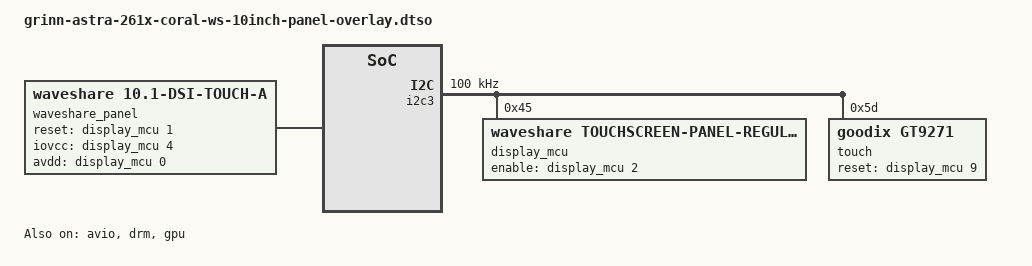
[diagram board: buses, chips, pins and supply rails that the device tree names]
/*
 * Device-tree overlay for the Waveshare 10.1" DSI Touch (A) panel
 * (SKU 30052) on the Grinn Astra 2619 Coral board.
 *
 *   Display IC : Jadard JD9365 (1280x800 native portrait, MIPI-DSI 2-lane)
 *   Touch IC   : Goodix GT9271
 *   Panel MCU  : Waveshare touchscreen panel regulator (I2C @ 0x45)
 *
 * The DSI host (syna_drm) is configured with the panel's native portrait
 * timings (800x1280) and sends the JD9365 init DCS sequence itself. The
 * panel-waveshare-touch kernel driver registers the drm_panel that the
 * DSI host attaches to via of_drm_find_panel(); it sequences the iovcc /
 * avdd / reset GPIOs that the Waveshare panel MCU exposes through the
 * waveshare-panel-regulator gpio_chip.
 */

/dts-v1/;
/plugin/;

#include <dt-bindings/gpio/gpio.h>

/ {
	compatible = "grinn,grinn-astra-2619-coral";
};

/*
 * Add the panel adapter node at the device-tree root via path-based
 * fragment syntax. The simpler `/ { ... };` form above is treated by
 * /plugin/ overlays as a root-match assertion only — subnodes inside
 * it are NOT emitted as fragments and never reach the live DT.
 *
 * &{/} forces a proper fragment with target = <&{/}>, which makes the
 * applicator add the child node at root. The kernel's of_platform
 * populate then creates a platform_device that panel-waveshare-dsi-v2
 * can bind to.
 */
&{/} {
	waveshare_panel: waveshare-panel {
		compatible = "waveshare,10.1-dsi-touch-a";
		status = "okay";
		reset-gpios = <&display_mcu 1 GPIO_ACTIVE_HIGH>;
		iovcc-gpios = <&display_mcu 4 GPIO_ACTIVE_HIGH>;
		avdd-gpios = <&display_mcu 0 GPIO_ACTIVE_HIGH>;
	};
};

&avio {
	status = "okay";
};

&drm {
	status = "okay";

	dsi_panel {
		status = "okay";

		backlight = <&display_mcu>;
		compatible_panel = "waveshare,10.1-dsi-touch-a";

		ACTIVE_WIDTH = <800>;
		HFP = <40>;
		HSYNCWIDTH = <20>;
		HBP = <20>;
		ACTIVE_HEIGHT = <1280>;
		VFP = <20>;
		VSYNCWIDTH = <20>;
		VBP = <4>;
		FREQ = <70000>;
		bits_per_pixel = <24>;
		busformat = <0>;

		HTOTAL = <880>;
		Lanes = /bits/ 8 <2>;
		Vid_mode = /bits/ 8 <1>;
		virtual_chan = /bits/ 8 <0>;
		Clk_Lane_Polarity = /bits/ 8 <0>;
		Data_Lane_Polarity = /bits/ 8 <0>;
		Recv_ack = /bits/ 8 <0>;
		Loosely_18 = /bits/ 8 <0>;
		H_polarity = /bits/ 8 <1>;
		V_Polarity = /bits/ 8 <1>;
		Data_Polarity = /bits/ 8 <1>;
		Eotp_tx = /bits/ 8 <0>;
		Eotp_rx = /bits/ 8 <0>;
		non-Continuous_clk = /bits/ 8 <1>;
		dpi_lp_cmd = /bits/ 8 <1>;
		Color_coding = /bits/ 8 <5>;
		Chunks = <0>;
		Null_Pkt = <0>;
		Byte_clk = <105000>;

		/*
		 * JD9365 init sequence transcribed from
		 * raspberrypi/linux rpi-6.12.y
		 *   drivers/gpu/drm/panel/panel-waveshare-dsi-v2.c
		 *   ws_panel_10_1_a_init[]
		 *
		 * Encoding (drivers/synaptics/.../drm/asxxx/dsi/includes.h):
		 *   0x05 LEN <reg>           DCS short write, 0 param
		 *   0x15 LEN <reg> <val>     DCS short write, 1 param
		 *   0xFF <us LE u32>         delay in microseconds
		 *
		 * 201 DCS commands + 2 delays = 812 bytes.
		 */
		command = /bits/ 8 <
				0x15 0x02 0xE0 0x00 0x15 0x02 0xE1 0x93
				0x15 0x02 0xE2 0x65 0x15 0x02 0xE3 0xF8
				0x15 0x02 0x80 0x01 0x15 0x02 0xE0 0x01
				0x15 0x02 0x00 0x00 0x15 0x02 0x01 0x38
				0x15 0x02 0x03 0x10 0x15 0x02 0x04 0x38
				0x15 0x02 0x0C 0x74 0x15 0x02 0x17 0x00
				0x15 0x02 0x18 0xAF 0x15 0x02 0x19 0x00
				0x15 0x02 0x1A 0x00 0x15 0x02 0x1B 0xAF
				0x15 0x02 0x1C 0x00 0x15 0x02 0x35 0x26
				0x15 0x02 0x37 0x09 0x15 0x02 0x38 0x04
				0x15 0x02 0x39 0x00 0x15 0x02 0x3A 0x01
				0x15 0x02 0x3C 0x78 0x15 0x02 0x3D 0xFF
				0x15 0x02 0x3E 0xFF 0x15 0x02 0x3F 0x7F
				0x15 0x02 0x40 0x06 0x15 0x02 0x41 0xA0
				0x15 0x02 0x42 0x81 0x15 0x02 0x43 0x1E
				0x15 0x02 0x44 0x0D 0x15 0x02 0x45 0x28
				/* 0x15 0x02 0x4A 0x35 */ /* Built-in self-test (BIST) command */
				0x15 0x02 0x55 0x02 0x15 0x02 0x57 0x69
				0x15 0x02 0x59 0x0A 0x15 0x02 0x5A 0x2A
				0x15 0x02 0x5B 0x17 0x15 0x02 0x5D 0x7F
				0x15 0x02 0x5E 0x6A 0x15 0x02 0x5F 0x5B
				0x15 0x02 0x60 0x4F 0x15 0x02 0x61 0x4A
				0x15 0x02 0x62 0x3D 0x15 0x02 0x63 0x41
				0x15 0x02 0x64 0x2A 0x15 0x02 0x65 0x44
				0x15 0x02 0x66 0x43 0x15 0x02 0x67 0x44
				0x15 0x02 0x68 0x62 0x15 0x02 0x69 0x52
				0x15 0x02 0x6A 0x59 0x15 0x02 0x6B 0x4C
				0x15 0x02 0x6C 0x48 0x15 0x02 0x6D 0x3A
				0x15 0x02 0x6E 0x26 0x15 0x02 0x6F 0x00
				0x15 0x02 0x70 0x7F 0x15 0x02 0x71 0x6A
				0x15 0x02 0x72 0x5B 0x15 0x02 0x73 0x4F
				0x15 0x02 0x74 0x4A 0x15 0x02 0x75 0x3D
				0x15 0x02 0x76 0x41 0x15 0x02 0x77 0x2A
				0x15 0x02 0x78 0x44 0x15 0x02 0x79 0x43
				0x15 0x02 0x7A 0x44 0x15 0x02 0x7B 0x62
				0x15 0x02 0x7C 0x52 0x15 0x02 0x7D 0x59
				0x15 0x02 0x7E 0x4C 0x15 0x02 0x7F 0x48
				0x15 0x02 0x80 0x3A 0x15 0x02 0x81 0x26
				0x15 0x02 0x82 0x00 0x15 0x02 0xE0 0x02
				0x15 0x02 0x00 0x42 0x15 0x02 0x01 0x42
				0x15 0x02 0x02 0x40 0x15 0x02 0x03 0x40
				0x15 0x02 0x04 0x5E 0x15 0x02 0x05 0x5E
				0x15 0x02 0x06 0x5F 0x15 0x02 0x07 0x5F
				0x15 0x02 0x08 0x5F 0x15 0x02 0x09 0x57
				0x15 0x02 0x0A 0x57 0x15 0x02 0x0B 0x77
				0x15 0x02 0x0C 0x77 0x15 0x02 0x0D 0x47
				0x15 0x02 0x0E 0x47 0x15 0x02 0x0F 0x45
				0x15 0x02 0x10 0x45 0x15 0x02 0x11 0x4B
				0x15 0x02 0x12 0x4B 0x15 0x02 0x13 0x49
				0x15 0x02 0x14 0x49 0x15 0x02 0x15 0x5F
				0x15 0x02 0x16 0x41 0x15 0x02 0x17 0x41
				0x15 0x02 0x18 0x40 0x15 0x02 0x19 0x40
				0x15 0x02 0x1A 0x5E 0x15 0x02 0x1B 0x5E
				0x15 0x02 0x1C 0x5F 0x15 0x02 0x1D 0x5F
				0x15 0x02 0x1E 0x5F 0x15 0x02 0x1F 0x57
				0x15 0x02 0x20 0x57 0x15 0x02 0x21 0x77
				0x15 0x02 0x22 0x77 0x15 0x02 0x23 0x46
				0x15 0x02 0x24 0x46 0x15 0x02 0x25 0x44
				0x15 0x02 0x26 0x44 0x15 0x02 0x27 0x4A
				0x15 0x02 0x28 0x4A 0x15 0x02 0x29 0x48
				0x15 0x02 0x2A 0x48 0x15 0x02 0x2B 0x5F
				0x15 0x02 0x2C 0x01 0x15 0x02 0x2D 0x01
				0x15 0x02 0x2E 0x00 0x15 0x02 0x2F 0x00
				0x15 0x02 0x30 0x1F 0x15 0x02 0x31 0x1F
				0x15 0x02 0x32 0x1E 0x15 0x02 0x33 0x1E
				0x15 0x02 0x34 0x1F 0x15 0x02 0x35 0x17
				0x15 0x02 0x36 0x17 0x15 0x02 0x37 0x37
				0x15 0x02 0x38 0x37 0x15 0x02 0x39 0x08
				0x15 0x02 0x3A 0x08 0x15 0x02 0x3B 0x0A
				0x15 0x02 0x3C 0x0A 0x15 0x02 0x3D 0x04
				0x15 0x02 0x3E 0x04 0x15 0x02 0x3F 0x06
				0x15 0x02 0x40 0x06 0x15 0x02 0x41 0x1F
				0x15 0x02 0x42 0x02 0x15 0x02 0x43 0x02
				0x15 0x02 0x44 0x00 0x15 0x02 0x45 0x00
				0x15 0x02 0x46 0x1F 0x15 0x02 0x47 0x1F
				0x15 0x02 0x48 0x1E 0x15 0x02 0x49 0x1E
				0x15 0x02 0x4A 0x1F 0x15 0x02 0x4B 0x17
				0x15 0x02 0x4C 0x17 0x15 0x02 0x4D 0x37
				0x15 0x02 0x4E 0x37 0x15 0x02 0x4F 0x09
				0x15 0x02 0x50 0x09 0x15 0x02 0x51 0x0B
				0x15 0x02 0x52 0x0B 0x15 0x02 0x53 0x05
				0x15 0x02 0x54 0x05 0x15 0x02 0x55 0x07
				0x15 0x02 0x56 0x07 0x15 0x02 0x57 0x1F
				0x15 0x02 0x58 0x40 0x15 0x02 0x5B 0x30
				0x15 0x02 0x5C 0x00 0x15 0x02 0x5D 0x34
				0x15 0x02 0x5E 0x05 0x15 0x02 0x5F 0x02
				0x15 0x02 0x63 0x00 0x15 0x02 0x64 0x6A
				0x15 0x02 0x67 0x73 0x15 0x02 0x68 0x07
				0x15 0x02 0x69 0x08 0x15 0x02 0x6A 0x6A
				0x15 0x02 0x6B 0x08 0x15 0x02 0x6C 0x00
				0x15 0x02 0x6D 0x00 0x15 0x02 0x6E 0x00
				0x15 0x02 0x6F 0x88 0x15 0x02 0x75 0xFF
				0x15 0x02 0x77 0xDD 0x15 0x02 0x78 0x2C
				0x15 0x02 0x79 0x15 0x15 0x02 0x7A 0x17
				0x15 0x02 0x7D 0x14 0x15 0x02 0x7E 0x82
				0x15 0x02 0xE0 0x04 0x15 0x02 0x00 0x0E
				0x15 0x02 0x02 0xB3 0x15 0x02 0x09 0x61
				0x15 0x02 0x0E 0x48 0x15 0x02 0x37 0x58
				0x15 0x02 0x2B 0x0F 0x15 0x02 0xE0 0x00
				0x15 0x02 0xE6 0x02 0x15 0x02 0xE7 0x0C
				0x05 0x01 0x11 0xFF 0xC0 0xD4 0x01 0x00
				0x05 0x01 0x29 0xFF 0x60 0xEA 0x00 0x00>;
	};
};

&gpu {
	status = "okay";
};

&i2c3 {
	clock-frequency = <100000>;
	/delete-property/ i2c-sda-hold-time-ns;
	/delete-property/ i2c-sda-falling-time-ns;
	/delete-property/ i2c-scl-falling-time-ns;

	display_mcu: display_mcu@45 {
		compatible = "waveshare,touchscreen-panel-regulator";
		reg = <0x45>;
		gpio-controller;
		#gpio-cells = <2>;
		/*
		 * BL_ENABLE (BIT 2) on the panel MCU's own gpio_chip.
		 * The waveshare-panel-regulator driver toggles this from
		 * its backlight update_status() to gate the backlight on
		 * and off; without it only the PWM register is updated.
		 */
		enable-gpios = <&display_mcu 2 GPIO_ACTIVE_HIGH>;
	};

	touch: goodix@5d {
		compatible = "goodix,gt9271";
		status = "okay";
		reg = <0x5d>;
		reset-gpios = <&display_mcu 9 GPIO_ACTIVE_HIGH>;
	};
};
